AUTOSAR XML (schema 4-0-3)
package /ComponentTypes
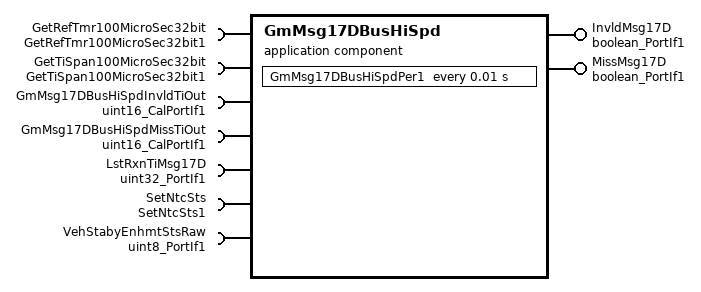
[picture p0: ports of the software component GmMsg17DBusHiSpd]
  application sw component type GmMsg17DBusHiSpd
    provide port InvldMsg17D: nonqueued-sender-com-spec{data-element=Logl, init-value=0}, provided-interface=boolean_PortIf1
    provide port MissMsg17D: nonqueued-sender-com-spec{data-element=Logl, init-value=0}, provided-interface=boolean_PortIf1
    7 x require port:
      GetRefTmr100MicroSec32bit: required-interface=GetRefTmr100MicroSec32bit1
      GetTiSpan100MicroSec32bit: required-interface=GetTiSpan100MicroSec32bit1
      GmMsg17DBusHiSpdInvldTiOut: parameter-require-com-spec{init-value=1000, parameter=Val}, required-interface=uint16_CalPortIf1
      GmMsg17DBusHiSpdMissTiOut: parameter-require-com-spec{init-value=500, parameter=Val}, required-interface=uint16_CalPortIf1
      LstRxnTiMsg17D: nonqueued-receiver-com-spec{data-element=Val, filter=data-filter-type=ALWAYS, init-value=0}, required-interface=uint32_PortIf1
      SetNtcSts: required-interface=SetNtcSts1
      VehStabyEnhmtStsRaw: nonqueued-receiver-com-spec{data-element=Val, filter=data-filter-type=ALWAYS, init-value=0}, required-interface=uint8_PortIf1
    behavior GmMsg17DBusHiSpd_InternalBehavior: data-type-mapping=Nexteer
      ar-typed-per-instance-memorys:
        data GmMsg17DBusHiSpdInvldMsgTmr: sw-calibration-access=READ-ONLY, type=uint32
      timing event TMT_GM0C9HSPer1: start-on-event=GmMsg17DBusHiSpdPer1, period=0.01
      runnable GmMsg17DBusHiSpdPer1
        data-receive-point-by-arguments:
          access REC_Msg0C9HSLstRxnTi_Val: accessed-variable=LstRxnTiMsg17D.Val
          access REC_VehStabyEnhmtStsRaw_Val: accessed-variable=VehStabyEnhmtStsRaw.Val
        data-send-points:
          access SEND_GM0C9HSMsgMiss_Logl: accessed-variable=MissMsg17D.Logl
          access SEND_InvldMsg17D_Logl: accessed-variable=InvldMsg17D.Logl
        sync call SC_GetRefTmr100MicroSec32bit_Oper: operation=GetRefTmr100MicroSec32bit.Oper, timeout=0
        sync call SC_GetTiSpan100MicroSec32bit_Oper: operation=GetTiSpan100MicroSec32bit.Oper, timeout=0
        sync call SC_SetNtcSts_Oper: operation=SetNtcSts.Oper, timeout=0
  swc implementation GmMsg17DBusHiSpd_Implementation: behavior=GmMsg17DBusHiSpd_InternalBehavior
    code-descriptors:
      code Default: artifact-descriptors=autosar-engineering-object={short-label=Default, category=SWSRC}
